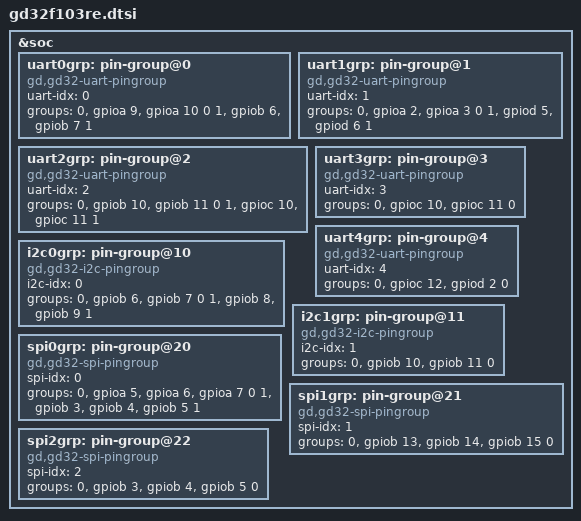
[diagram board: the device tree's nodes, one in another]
/*
 * gd32f103re.dtsi —— GD32F103RE 型号级设备树 (高密度 HD, LQFP64)
 *
 * 在家族公共部分 (gd32f10x.dtsi) 之上, 补充本型号可用的 UART 引脚分组。
 * 引脚能力依据 GD32F103xx Datasheet Rev3.2 表 2-7 (LQFP64)。
 *
 * 新增其他型号 (如 gd32f103rc / gd32f103rb):
 *   复制本文件改名 -> 按对应型号数据手册 2.6 节(对应封装引脚表)裁剪/修改
 *   引脚组(RE 为 HD 高密度, RC/RB 的 USART2 全重映射组 PD8~PD12 仅
 *   100/144 脚封装才有, 64 脚封装不可用) -> 板级 .dts 改 include 新型号。
 */

#include "gd32f10x.dtsi"

&soc {
	/* ------------------------------------------------------------------
	 * UART 引脚分组 (借用 Linux pinctrl 思想): 把数据手册 2.6 节中
	 * 每个串口可选的 TX/RX 引脚组合预定义成组, 板级 dts 用
	 * pgroup = <&usart0 0> 选择; 第 2 个单元是组号:
	 *   0 = m0 默认组 (USART0: PA9/PA10, USART1: PA2/PA3, ...)
	 *   1 = m1 重映射组 (USART0: PB6/PB7, USART2: PC10/PC11, ...)
	 * 用户也可以不用预定义组, 在板级 dts 直接写 tx-gpios/rx-gpios
	 * 手动组合, 只要引脚在数据手册中标了对应的 USARTx_TX/RX
	 * 复用功能即可。
	 * ------------------------------------------------------------------ */
	uart0grp: pin-group@0 {
		compatible = "gd,gd32-uart-pingroup";
		uart-idx = <0>;
		groups = <
			/* m0: PA9=USART0_TX,  PA10=USART0_RX (默认, 不重映射) */
			0 &gpioa 9 &gpioa 10 0
			/* m1: PB6=USART0_TX,  PB7=USART0_RX  (重映射) */
			1 &gpiob 6 &gpiob 7 1>;
	};

	uart1grp: pin-group@1 {
		compatible = "gd,gd32-uart-pingroup";
		uart-idx = <1>;
		groups = <
			/* m0: PA2=USART1_TX, PA3=USART1_RX (默认) */
			0 &gpioa 2 &gpioa 3 0
			/* m1: PD5=USART1_TX, PD6=USART1_RX (重映射, 仅 100/144 脚) */
			1 &gpiod 5 &gpiod 6 1>;
	};

	uart2grp: pin-group@2 {
		compatible = "gd,gd32-uart-pingroup";
		uart-idx = <2>;
		groups = <
			/* m0: PB10=USART2_TX, PB11=USART2_RX (默认) */
			0 &gpiob 10 &gpiob 11 0
			/* m1: PC10=USART2_TX, PC11=USART2_RX (部分重映射, 64 脚可用) */
			1 &gpioc 10 &gpioc 11 1>;
	};

	uart3grp: pin-group@3 {
		compatible = "gd,gd32-uart-pingroup";
		uart-idx = <3>;
		groups = <
			/* m0: PC10=UART3_TX, PC11=UART3_RX (固定, 无重映射) */
			0 &gpioc 10 &gpioc 11 0>;
	};

	uart4grp: pin-group@4 {
		compatible = "gd,gd32-uart-pingroup";
		uart-idx = <4>;
		groups = <
			/* m0: PC12=UART4_TX, PD2=UART4_RX (固定, 无重映射) */
			0 &gpioc 12 &gpiod 2 0>;
	};

	/* ------------------------------------------------------------------
	 * I2C 引脚分组: 每个条目 6 个单元 <组号 &SCL端口 SCL脚 &SDA端口 SDA脚 重映射>
	 * SCL/SDA 由驱动配置为复用开漏 (GPIO_MODE_AF_OD), 总线需外部上拉电阻
	 * ------------------------------------------------------------------ */
	i2c0grp: pin-group@10 {
		compatible = "gd,gd32-i2c-pingroup";
		i2c-idx = <0>;
		groups = <
			/* m0: PB6=I2C0_SCL, PB7=I2C0_SDA (默认, 不重映射) */
			0 &gpiob 6 &gpiob 7 0
			/* m1: PB8=I2C0_SCL, PB9=I2C0_SDA (重映射) */
			1 &gpiob 8 &gpiob 9 1>;
	};

	i2c1grp: pin-group@11 {
		compatible = "gd,gd32-i2c-pingroup";
		i2c-idx = <1>;
		groups = <
			/* m0: PB10=I2C1_SCL, PB11=I2C1_SDA (固定, 无重映射) */
			0 &gpiob 10 &gpiob 11 0>;
	};

	/* ------------------------------------------------------------------
	 * SPI 引脚分组: 每个条目 8 个单元
	 *   <组号 &SCK端口 SCK脚 &MISO端口 MISO脚 &MOSI端口 MOSI脚 重映射>
	 * SCK/MOSI 由驱动配置为复用推挽, MISO 浮空输入; 片选用软 CS (cs-gpios)
	 * 注意: PA15/PB3/PB4 上电默认是 JTAG 引脚 (JTDO/NJTRST/JTDI),
	 * 驱动用到时会自动禁 JTAG 保留 SWD (PA13/PA14 可继续调试)
	 * ------------------------------------------------------------------ */
	spi0grp: pin-group@20 {
		compatible = "gd,gd32-spi-pingroup";
		spi-idx = <0>;
		groups = <
			/* m0: PA5=SCK, PA6=MISO, PA7=MOSI (默认, 不重映射) */
			0 &gpioa 5 &gpioa 6 &gpioa 7 0
			/* m1: PB3=SCK, PB4=MISO, PB5=MOSI (重映射, PA15=NSS 不用) */
			1 &gpiob 3 &gpiob 4 &gpiob 5 1>;
	};

	spi1grp: pin-group@21 {
		compatible = "gd,gd32-spi-pingroup";
		spi-idx = <1>;
		groups = <
			/* m0: PB13=SCK, PB14=MISO, PB15=MOSI (固定, 无重映射) */
			0 &gpiob 13 &gpiob 14 &gpiob 15 0>;
	};

	spi2grp: pin-group@22 {
		compatible = "gd,gd32-spi-pingroup";
		spi-idx = <2>;
		groups = <
			/* m0: PB3=SCK, PB4=MISO, PB5=MOSI (固定; 与 SPI0 重映射组共用引脚, 二者只能取其一) */
			0 &gpiob 3 &gpiob 4 &gpiob 5 0>;
	};
};
